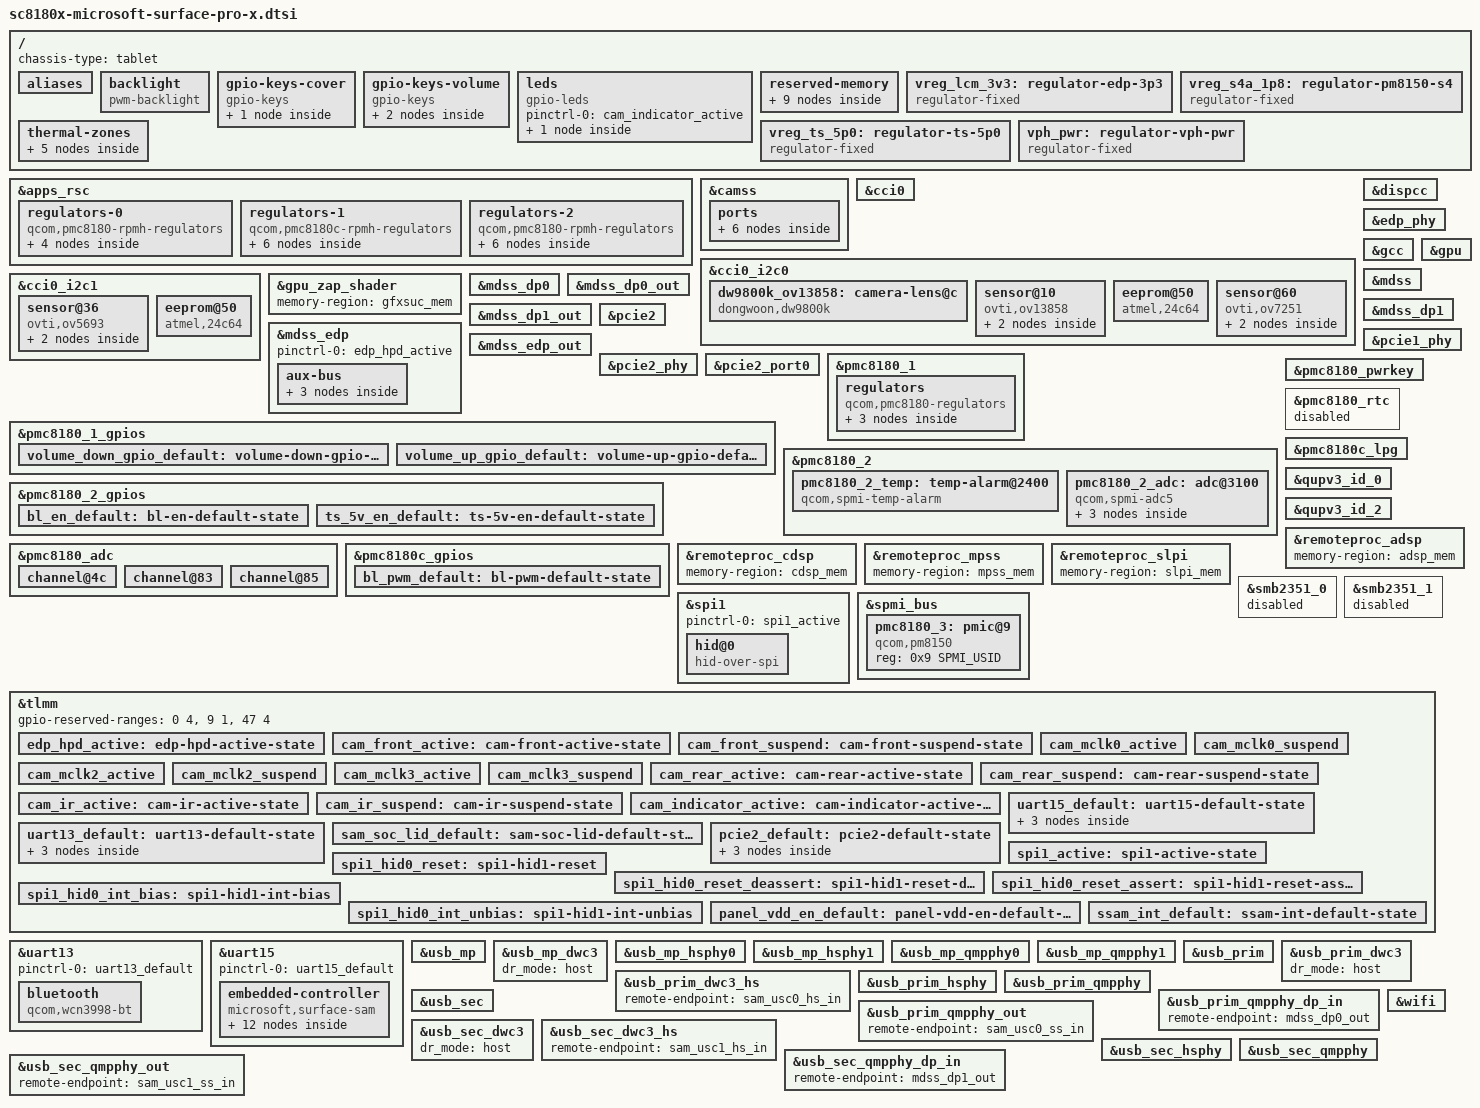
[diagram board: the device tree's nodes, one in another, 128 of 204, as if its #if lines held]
// SPDX-License-Identifier: (GPL-2.0+ OR BSD-3-Clause)
/*
 * Copyright (c) 2022-2026, Maximilian Luz <luzmaximilian@gmail.com>
 * Copyright (c) 2026, Val Packett <val@packett.cool>
 */

/dts-v1/;

#include <dt-bindings/firmware/qcom,scm.h>
#include <dt-bindings/gpio/gpio.h>
#include <dt-bindings/iio/qcom,spmi-vadc.h>
#include <dt-bindings/input/gpio-keys.h>
#include <dt-bindings/input/input.h>
#include <dt-bindings/interrupt-controller/irq.h>
#include <dt-bindings/leds/common.h>
#include <dt-bindings/media/video-interface-devices.h>
#include <dt-bindings/media/video-interfaces.h>
#include <dt-bindings/regulator/qcom,rpmh-regulator.h>
#include <dt-bindings/spmi/spmi.h>
#include "sc8180x.dtsi"
#include "sc8180x-pmics.dtsi"

/delete-node/ &gpu_mem;

/ {
	chassis-type = "tablet";

	aliases {
		serial0 = &uart13;
		serial1 = &uart15;
	};

	backlight: backlight {
		compatible = "pwm-backlight";

		pwms = <&pmc8180c_lpg 4 5000000>;
		enable-gpios = <&pmc8180_2_gpios 1 GPIO_ACTIVE_HIGH>;

		pinctrl-0 = <&bl_pwm_default &bl_en_default>;
		pinctrl-names = "default";
	};

	gpio-keys-cover {
		compatible = "gpio-keys";
		label = "Tablet Cover Switch";

		pinctrl-0 = <&sam_soc_lid_default>;
		pinctrl-names = "default";

		switch-cover {
			label = "Tablet Cover";
			gpios = <&tlmm 121 GPIO_ACTIVE_LOW>;
			linux,input-type = <EV_SW>;
			linux,code = <SW_LID>;
			wakeup-source;
			wakeup-event-action = <EV_ACT_DEASSERTED>;
		};
	};

	gpio-keys-volume {
		compatible = "gpio-keys";
		label = "Volume Buttons";
		autorepeat;

		pinctrl-0 = <&volume_down_gpio_default>,
			   <&volume_up_gpio_default>;
		pinctrl-names = "default";

		key-volume-down {
			label = "Volume Down";
			gpios = <&pmc8180_1_gpios 1 GPIO_ACTIVE_LOW>;
			wakeup-source;
			linux,code = <KEY_VOLUMEDOWN>;
		};

		key-volume-up {
			label = "Volume Up";
			gpios = <&pmc8180_1_gpios 6 GPIO_ACTIVE_LOW>;
			wakeup-source;
			linux,code = <KEY_VOLUMEUP>;
		};
	};

	leds {
		compatible = "gpio-leds";

		pinctrl-0 = <&cam_indicator_active>;
		pinctrl-names = "default";

		privacy_led: led-camera-indicator {
			label = "white:camera-indicator";
			function = LED_FUNCTION_INDICATOR;
			color = <LED_COLOR_ID_WHITE>;
			gpios = <&tlmm 25 GPIO_ACTIVE_HIGH>;
			linux,default-trigger = "none";
			default-state = "off";
			panic-indicator;
		};
	};

	reserved-memory {
		rmtfs_mem: memory@85500000 {
			compatible = "qcom,rmtfs-mem";
			reg = <0x0 0x85500000 0x0 0x200000>;
			no-map;

			qcom,client-id = <1>;
			qcom,vmid = <QCOM_SCM_VMID_MSS_MSA>;
		};

		wlan_mem: memory@8bc00000 {
			reg = <0x0 0x8bc00000 0x0 0x180000>;
			no-map;
		};

		mpss_mem: memory@8d800000 { /* non-relocatable */
			reg = <0x0 0x8d800000 0x0 0x9600000>;
			no-map;
		};

		adsp_mem: memory@96e00000 {
			reg = <0x0 0x96e00000 0x0 0x1c00000>;
			no-map;
		};

		cdsp_mem: memory@98a00000 {
			reg = <0x0 0x98a00000 0x0 0x800000>;
			no-map;
		};

		slpi_mem: memory@99200000 {
			reg = <0x0 0x99200000 0x0 0x1400000>;
			no-map;
		};

		venus_mem: memory@9a600000 {
			reg = <0x0 0x9a600000 0x0 0x500000>;
			no-map;
		};

		gfxsuc_mem: memory@9ab00000 {
			reg = <0x0 0x9ab00000 0x0 0x5000>;
			no-map;
		};

		linux,cma {
			compatible = "shared-dma-pool";
			size = <0x0 0x8000000>;
			reusable;
			linux,cma-default;
		};
	};

	vreg_lcm_3v3: regulator-edp-3p3 {
		compatible = "regulator-fixed";

		regulator-name = "VREG_LCM_3V3";
		regulator-min-microvolt = <3300000>;
		regulator-max-microvolt = <3300000>;

		gpio = <&tlmm 130 GPIO_ACTIVE_HIGH>;
		enable-active-high;

		pinctrl-0 = <&panel_vdd_en_default>;
		pinctrl-names = "default";

		regulator-boot-on;
	};

	vreg_s4a_1p8: regulator-pm8150-s4 {
		compatible = "regulator-fixed";
		regulator-name = "vreg_s4a_1p8";

		regulator-min-microvolt = <1800000>;
		regulator-max-microvolt = <1800000>;

		regulator-always-on;
		regulator-boot-on;

		vin-supply = <&vph_pwr>;
	};

	vreg_ts_5p0: regulator-ts-5p0 {
		compatible = "regulator-fixed";
		regulator-name = "vreg_ts_5p0";

		regulator-min-microvolt = <5000000>;
		regulator-max-microvolt = <5000000>;

		gpio = <&pmc8180_2_gpios 10 GPIO_ACTIVE_HIGH>;
		enable-active-high;

		pinctrl-names = "default";
		pinctrl-0 = <&ts_5v_en_default>;
	};

	vph_pwr: regulator-vph-pwr {
		compatible = "regulator-fixed";
		regulator-name = "vph_pwr";
		regulator-min-microvolt = <3700000>;
		regulator-max-microvolt = <3700000>;

		regulator-always-on;
		regulator-boot-on;
	};

	thermal-zones {
		pmc8180-2-thermal {
			polling-delay-passive = <100>;
			polling-delay = <0>;

			thermal-sensors = <&pmc8180_2_temp>;

			trips {
				trip0 {
					temperature = <95000>;
					hysteresis = <0>;
					type = "passive";
				};

				trip1 {
					temperature = <115000>;
					hysteresis = <0>;
					type = "hot";
				};

				trip2 {
					temperature = <145000>;
					hysteresis = <0>;
					type = "critical";
				};
			};
		};
	};
};

&apps_rsc {
	regulators-0 {
		compatible = "qcom,pmc8180-rpmh-regulators";
		qcom,pmic-id = "a";

		vdd-s1-supply = <&vph_pwr>;
		vdd-s2-supply = <&vph_pwr>;
		vdd-s3-supply = <&vph_pwr>;
		vdd-s4-supply = <&vph_pwr>;
		vdd-s5-supply = <&vph_pwr>;
		vdd-s6-supply = <&vph_pwr>;
		vdd-s7-supply = <&vph_pwr>;
		vdd-s8-supply = <&vph_pwr>;
		vdd-s9-supply = <&vph_pwr>;
		vdd-s10-supply = <&vph_pwr>;

		vdd-l1-l8-l11-supply = <&vreg_s6c_1p37>;
		vdd-l2-l10-supply = <&vreg_bob>;
		vdd-l3-l4-l5-l18-supply = <&vreg_s7c_0p96>;
		vdd-l6-l9-supply = <&vreg_s6c_1p37>;
		vdd-l7-l12-l14-l15-supply = <&vreg_s5a_2p04>;
		vdd-l13-l16-l17-supply = <&vreg_bob>;

		vreg_s5a_2p04: smps5 {
			regulator-min-microvolt = <2040000>;
			regulator-max-microvolt = <2040000>;
		};

		vreg_l7a_1p8: ldo7 {
			regulator-min-microvolt = <1800000>;
			regulator-max-microvolt = <1800000>;
			regulator-initial-mode = <RPMH_REGULATOR_MODE_HPM>;
		};

		vreg_l9a_1p3: ldo9 {
			regulator-min-microvolt = <1296000>;
			regulator-max-microvolt = <1304000>;
			regulator-initial-mode = <RPMH_REGULATOR_MODE_HPM>;
		};

		vreg_l12a_1p8: ldo12 {
			regulator-min-microvolt = <1800000>;
			regulator-max-microvolt = <1800000>;
			regulator-initial-mode = <RPMH_REGULATOR_MODE_HPM>;
		};
	};

	regulators-1 {
		compatible = "qcom,pmc8180c-rpmh-regulators";
		qcom,pmic-id = "c";

		vdd-s1-supply = <&vph_pwr>;
		vdd-s2-supply = <&vph_pwr>;
		vdd-s3-supply = <&vph_pwr>;
		vdd-s4-supply = <&vph_pwr>;
		vdd-s5-supply = <&vph_pwr>;
		vdd-s6-supply = <&vph_pwr>;
		vdd-s7-supply = <&vph_pwr>;
		vdd-s8-supply = <&vph_pwr>;

		vdd-l1-l8-supply = <&vreg_s4a_1p8>;
		vdd-l2-l3-supply = <&vreg_s6c_1p37>;
		vdd-l4-l5-l6-supply = <&vreg_bob>;
		vdd-l7-l11-supply = <&vreg_bob>;
		vdd-l9-l10-supply = <&vreg_bob>;

		vdd-bob-supply = <&vph_pwr>;
		vdd-flash-supply = <&vreg_bob>;
		vdd-rgb-supply = <&vreg_bob>;

		vreg_s6c_1p37: smps6 {
			regulator-min-microvolt = <1350000>;
			regulator-max-microvolt = <1372000>;
			regulator-initial-mode = <RPMH_REGULATOR_MODE_HPM>;
		};

		vreg_s7c_0p96: smps7 {
			regulator-min-microvolt = <960000>;
			regulator-max-microvolt = <960000>;
			regulator-initial-mode = <RPMH_REGULATOR_MODE_HPM>;
		};

		vreg_l3c_1p2: ldo3 {
			regulator-min-microvolt = <1200000>;
			regulator-max-microvolt = <1200000>;
			regulator-initial-mode = <RPMH_REGULATOR_MODE_HPM>;
		};

		vreg_l10c_3p3: ldo10 {
			regulator-min-microvolt = <3296000>;
			regulator-max-microvolt = <3312000>;
			regulator-initial-mode = <RPMH_REGULATOR_MODE_HPM>;
		};

		vreg_l11c_3p3: ldo11 {
			regulator-min-microvolt = <3296000>;
			regulator-max-microvolt = <3304000>;
			regulator-initial-mode = <RPMH_REGULATOR_MODE_HPM>;
		};

		vreg_bob: bob {
			regulator-min-microvolt = <3296000>;
			regulator-max-microvolt = <3350000>;
			regulator-initial-mode = <RPMH_REGULATOR_MODE_HPM>;
		};
	};

	regulators-2 {
		compatible = "qcom,pmc8180-rpmh-regulators";
		qcom,pmic-id = "e";

		vdd-s1-supply = <&vph_pwr>;
		vdd-s2-supply = <&vph_pwr>;
		vdd-s3-supply = <&vph_pwr>;
		vdd-s4-supply = <&vph_pwr>;
		vdd-s5-supply = <&vph_pwr>;
		vdd-s6-supply = <&vph_pwr>;
		vdd-s7-supply = <&vph_pwr>;
		vdd-s8-supply = <&vph_pwr>;
		vdd-s9-supply = <&vph_pwr>;
		vdd-s10-supply = <&vph_pwr>;

		vdd-l1-l8-l11-supply = <&vreg_s4e_0p99>;
		vdd-l2-l10-supply = <&vreg_bob>;
		vdd-l3-l4-l5-l18-supply = <&vreg_s4e_0p99>;
		vdd-l6-l9-supply = <&vreg_s4e_0p99>;
		vdd-l7-l12-l14-l15-supply = <&vreg_s5e_2p04>;
		vdd-l13-l16-l17-supply = <&vreg_bob>;

		vreg_s4e_0p99: smps4 {
			regulator-min-microvolt = <992000>;
			regulator-max-microvolt = <992000>;
			regulator-initial-mode = <RPMH_REGULATOR_MODE_HPM>;
		};

		vreg_s5e_2p04: smps5 {
			regulator-min-microvolt = <2040000>;
			regulator-max-microvolt = <2040000>;
			regulator-initial-mode = <RPMH_REGULATOR_MODE_HPM>;
		};

		vreg_l1e_0p75: ldo1 {
			regulator-min-microvolt = <752000>;
			regulator-max-microvolt = <752000>;
			regulator-initial-mode = <RPMH_REGULATOR_MODE_HPM>;
		};

		vreg_l5e_0p88: ldo5 {
			regulator-min-microvolt = <880000>;
			regulator-max-microvolt = <880000>;
			regulator-initial-mode = <RPMH_REGULATOR_MODE_HPM>;
		};

		vreg_l9e_0p88: ldo9 {
			regulator-min-microvolt = <880000>;
			regulator-max-microvolt = <880000>;
			regulator-initial-mode = <RPMH_REGULATOR_MODE_HPM>;
		};

		vreg_l16e_3p1: ldo16 {
			regulator-min-microvolt = <3072000>;
			regulator-max-microvolt = <3072000>;
			regulator-initial-mode = <RPMH_REGULATOR_MODE_HPM>;
		};
	};
};

&camss {
	vdda-phy-supply = <&vreg_l5e_0p88>;
	vdda-pll-supply = <&vreg_l3c_1p2>;
	status = "okay";

	ports {
		port@0 {
			csiphy0_lanes01_ep: endpoint {
				clock-lanes = <7>;
				data-lanes = <0 1>;
				remote-endpoint = <&ov5693_ep>;
			};
		};

		port@2 {
			csiphy2_ep: endpoint {
				data-lanes = <0 1 2 3>;
				remote-endpoint = <&ov13858_ep>;
			};
		};

		port@3 {
			csiphy3_lane0_ep: endpoint {
				clock-lanes = <7>;
				data-lanes = <0>;
				remote-endpoint = <&ov7251_ep>;
			};
		};
	};
};

&cci0 {
	status = "okay";
};

&cci0_i2c0 {
#ifdef NOTYET
	// XXX: doesn't like being accessed when camera itself is not streaming??
	dw9800k_ov13858: camera-lens@c {
		compatible = "dongwoon,dw9800k";
		reg = <0x0c>;

		vdd-supply = <&vreg_l17a_2p85>;

		dongwoon,sac-mode = <1>;
		dongwoon,vcm-prescale = <16>;
	};
#endif

	sensor@10 {
		compatible = "ovti,ov13858";
		reg = <0x10>;

		avdd-supply = <&vreg_l17a_2p85>;
		dovdd-supply = <&vreg_l14a_1p8>;
		dvdd-supply = <&vreg_l1a_1p2>;

		pinctrl-names = "default", "sleep";
		pinctrl-0 = <&cam_mclk0_active &cam_rear_active>;
		pinctrl-1 = <&cam_mclk0_suspend &cam_rear_suspend>;

		clocks = <&camcc CAM_CC_MCLK0_CLK>;
		assigned-clocks = <&camcc CAM_CC_MCLK0_CLK>;
		assigned-clock-rates = <19200000>;

		/* CAM_REAR_PWRDN_N, functions as inverted reset */
		reset-gpios = <&tlmm 22 GPIO_ACTIVE_LOW>;

		orientation = <MEDIA_ORIENTATION_BACK>;
		rotation = <180>;

		// lens-focus = <&dw9800k_ov13858>;

		port {
			ov13858_ep: endpoint {
				bus-type = <MEDIA_BUS_TYPE_CSI2_DPHY>;
				data-lanes = <1 2 3 4>;
				link-frequencies = /bits/ 64 <540000000 270000000>;
				remote-endpoint = <&csiphy2_ep>;
			};
		};
	};

	eeprom@50 {
		compatible = "atmel,24c64";
		reg = <0x50>;
		vcc-supply = <&vreg_l14a_1p8>;
		read-only;
	};

	sensor@60 {
		compatible = "ovti,ov7251";
		reg = <0x60>;

		vdda-supply = <&vreg_l14a_1p8>;
		vddd-supply = <&vreg_l14a_1p8>;
		vdddo-supply = <&vreg_l14a_1p8>;

		pinctrl-names = "default", "sleep";
		pinctrl-0 = <&cam_mclk3_active &cam_ir_active>;
		pinctrl-1 = <&cam_mclk3_suspend &cam_ir_suspend>;

		clocks = <&camcc CAM_CC_MCLK3_CLK>;
		clock-names = "xclk";
		assigned-clocks = <&camcc CAM_CC_MCLK3_CLK>;
		assigned-clock-rates = <19200000>;

		/* CAM_IR_PWRDN_N; driver's confused and treats reset as pwrdn */
		enable-gpios = <&tlmm 23 GPIO_ACTIVE_HIGH>;

		orientation = <MEDIA_ORIENTATION_FRONT>;

		port {
			ov7251_ep: endpoint {
				bus-type = <MEDIA_BUS_TYPE_CSI2_DPHY>;
				data-lanes = <1>;
				link-frequencies = /bits/ 64 <240000000 319200000>;
				remote-endpoint = <&csiphy3_lane0_ep>;
			};
		};
	};
};

&cci0_i2c1 {
	sensor@36 {
		compatible = "ovti,ov5693";
		reg = <0x36>;

		// LDO makes avdd2.8V, enabled also by l14a itself(!)
		avdd-supply = <&vreg_l14a_1p8>;
		dvdd-supply = <&vreg_l14a_1p8>;
		dovdd-supply = <&vreg_l14a_1p8>;

		pinctrl-names = "default", "sleep";
		pinctrl-0 = <&cam_mclk2_active &cam_front_active>;
		pinctrl-1 = <&cam_mclk2_suspend &cam_front_suspend>;

		/* CAM_FRONT_PWRDN_N; driver's confused and treats reset as pwrdn */
		reset-gpios = <&tlmm 12 GPIO_ACTIVE_LOW>;

		clocks = <&camcc CAM_CC_MCLK2_CLK>;
		clock-names = "xvclk";
		assigned-clocks = <&camcc CAM_CC_MCLK2_CLK>;
		assigned-clock-rates = <19200000>;

		orientation = <MEDIA_ORIENTATION_FRONT>;
		rotation = <180>;

		leds = <&privacy_led>;
		led-names = "privacy";

		port {
			ov5693_ep: endpoint {
				bus-type = <MEDIA_BUS_TYPE_CSI2_DPHY>;
				data-lanes = <1 2>;
				link-frequencies = /bits/ 64 <419200000>;
				remote-endpoint = <&csiphy0_lanes01_ep>;
			};
		};
	};

	eeprom@50 {
		compatible = "atmel,24c64";
		reg = <0x50>;
		vcc-supply = <&vreg_l14a_1p8>;
		read-only;
	};
};

&dispcc {
	status = "okay";
};

&edp_phy {
	vdda-pll-supply = <&vreg_l5e_0p88>;
	vdda-phy-supply = <&vreg_l3c_1p2>;
};

&gcc {
	protected-clocks = <GCC_QSPI_CORE_CLK>,
			   <GCC_QSPI_CORE_CLK_SRC>,
			   <GCC_QSPI_CNOC_PERIPH_AHB_CLK>;
};

&gpu {
	status = "okay";
};

&gpu_zap_shader {
	memory-region = <&gfxsuc_mem>;
};

&mdss {
	status = "okay";
};

&mdss_dp0 {
	status = "okay";
};

&mdss_dp0_out {
	data-lanes = <0 1>;
	remote-endpoint = <&usb_prim_qmpphy_dp_in>;
};

&mdss_dp1 {
	status = "okay";
};

&mdss_dp1_out {
	data-lanes = <0 1>;
	remote-endpoint = <&usb_sec_qmpphy_dp_in>;
};

&mdss_edp {
	pinctrl-0 = <&edp_hpd_active>;
	pinctrl-names = "default";

	status = "okay";

	aux-bus {
		panel {
			compatible = "edp-panel";
			power-supply = <&vreg_lcm_3v3>;

			backlight = <&backlight>;

			port {
				edp_panel_in: endpoint {
					remote-endpoint = <&mdss_edp_out>;
				};
			};
		};
	};
};

&mdss_edp_out {
	data-lanes = <0 1 2 3>;
	remote-endpoint = <&edp_panel_in>;
};

&pcie1_phy {
	vdda-phy-supply = <&vreg_l5e_0p88>;
	vdda-pll-supply = <&vreg_l3c_1p2>;

	status = "okay";
};

&pcie2 {
	// XXX: pcie1 and pcie2 are multi'd together, for now use just one
	num-lanes = <2>;

	pinctrl-0 = <&pcie2_default>;
	pinctrl-names = "default";

	// XXX: Remove "global" interrupt (breaks the multi workaround)
	interrupts = <GIC_SPI 672 IRQ_TYPE_LEVEL_HIGH>,
		     <GIC_SPI 671 IRQ_TYPE_LEVEL_HIGH>,
		     <GIC_SPI 670 IRQ_TYPE_LEVEL_HIGH>,
		     <GIC_SPI 669 IRQ_TYPE_LEVEL_HIGH>,
		     <GIC_SPI 668 IRQ_TYPE_LEVEL_HIGH>,
		     <GIC_SPI 667 IRQ_TYPE_LEVEL_HIGH>,
		     <GIC_SPI 666 IRQ_TYPE_LEVEL_HIGH>,
		     <GIC_SPI 665 IRQ_TYPE_LEVEL_HIGH>;
	interrupt-names = "msi0",
			  "msi1",
			  "msi2",
			  "msi3",
			  "msi4",
			  "msi5",
			  "msi6",
			  "msi7";

	status = "okay";
};

&pcie2_phy {
	vdda-phy-supply = <&vreg_l5e_0p88>;
	vdda-pll-supply = <&vreg_l3c_1p2>;

	status = "okay";
};

&pcie2_port0 {
	reset-gpios = <&tlmm 102 GPIO_ACTIVE_LOW>;
	wake-gpios = <&tlmm 104 GPIO_ACTIVE_LOW>;
};

&pmc8180_1 {
	regulators {
		compatible = "qcom,pmc8180-regulators";

		vdd_l1_l8_l11-supply = <&vreg_s6c_1p37>;
		vdd_l7_l12_l14_l15-supply = <&vreg_s5a_2p04>;
		vdd_l13_l16_l17-supply = <&vreg_bob>;

		vreg_l1a_1p2: l1 {
			regulator-name = "vreg_l1a_1p2";
			regulator-min-microvolt = <1200000>;
			regulator-max-microvolt = <1200000>;
			regulator-enable-ramp-delay = <10000>;
		};

		vreg_l14a_1p8: l14 {
			regulator-name = "vreg_l14a_1p8";
			regulator-min-microvolt = <1800000>;
			regulator-max-microvolt = <1800000>;
			regulator-enable-ramp-delay = <10000>;
		};

		vreg_l17a_2p85: l17 {
			regulator-name = "vreg_l17a_2p85";
			regulator-min-microvolt = <2848000>;
			regulator-max-microvolt = <2848000>;
			regulator-enable-ramp-delay = <10000>;
		};
	};
};

&pmc8180_1_gpios {
	volume_down_gpio_default: volume-down-gpio-default-state {
		pins = "gpio1";
		function = "normal";

		input-enable;
		bias-pull-up;

		qcom,drive-strength = <0>;
	};

	volume_up_gpio_default: volume-up-gpio-default-state {
		pins = "gpio6";
		function = "normal";

		input-enable;
		bias-pull-up;

		qcom,drive-strength = <0>;
	};
};

&pmc8180_2 {
	pmc8180_2_temp: temp-alarm@2400 {
		compatible = "qcom,spmi-temp-alarm";
		reg = <0x2400>;
		interrupts = <0x8 0x24 0x0 IRQ_TYPE_EDGE_BOTH>;
		io-channels = <&pmc8180_2_adc ADC5_DIE_TEMP>;
		io-channel-names = "thermal";
		#thermal-sensor-cells = <0>;
	};

	pmc8180_2_adc: adc@3100 {
		compatible = "qcom,spmi-adc5";
		reg = <0x3100>;
		#address-cells = <1>;
		#size-cells = <0>;
		#io-channel-cells = <1>;
		interrupts = <0x8 0x31 0x0 IRQ_TYPE_EDGE_RISING>;

		channel@0 {
			reg = <ADC5_REF_GND>;
			qcom,pre-scaling = <1 1>;
			label = "ref_gnd";
		};

		channel@1 {
			reg = <ADC5_1P25VREF>;
			qcom,pre-scaling = <1 1>;
			label = "vref_1p25";
		};

		channel@6 {
			reg = <ADC5_DIE_TEMP>;
			qcom,pre-scaling = <1 1>;
			label = "die_temp";
		};
	};
};

&pmc8180_2_gpios {
	bl_en_default: bl-en-default-state {
		pins = "gpio1";
		function = "normal";
	};

	ts_5v_en_default: ts-5v-en-default-state {
		pins = "gpio10";
		function = "normal";
	};
};

&pmc8180_adc {
	channel@4c {
		reg = <ADC5_XO_THERM_100K_PU>;
		qcom,ratiometric;
		qcom,pre-scaling = <1 1>;
		qcom,hw-settle-time = <200>;
		label = "xo_therm";
	};

	channel@83 {
		reg = <ADC5_VPH_PWR>;
		qcom,pre-scaling = <1 3>;
		label = "vph_pwr";
	};

	channel@85 {
		reg = <ADC5_VCOIN>;
		qcom,pre-scaling = <1 3>;
		label = "vcoin";
	};
};

&pmc8180_pwrkey {
	status = "okay";
};

&pmc8180_rtc {
	status = "disabled";
};

&pmc8180c_gpios {
	bl_pwm_default: bl-pwm-default-state {
		pins = "gpio10";
		function = "func1";
	};
};

&pmc8180c_lpg {
	status = "okay";
};

&qupv3_id_0 {
	status = "okay";
};

&qupv3_id_2 {
	status = "okay";
};

&remoteproc_adsp {
	memory-region = <&adsp_mem>;
};

&remoteproc_cdsp {
	memory-region = <&cdsp_mem>;
};

&remoteproc_mpss {
	memory-region = <&mpss_mem>;
};

&remoteproc_slpi {
	memory-region = <&slpi_mem>;
};

&smb2351_0 {
	status = "disabled";
};

&smb2351_1 {
	status = "disabled";
};

&spi1 {
	pinctrl-names = "default";
	pinctrl-0 = <&spi1_active>;

	status = "okay";

	hid@0 {
		compatible = "hid-over-spi";

		reg = <0>;
		spi-max-frequency = <25000000>;

		interrupts-extended = <&tlmm 122 IRQ_TYPE_EDGE_FALLING>;

		vdd-supply = <&vreg_ts_5p0>;

		pinctrl-0 = <&spi1_hid0_reset_deassert &spi1_hid0_int_bias>;
		pinctrl-1 = <&spi1_hid0_reset_assert &spi1_hid0_int_unbias>;
		pinctrl-2 = <&spi1_hid0_reset_assert &spi1_hid0_int_bias>;
		pinctrl-names = "active", "sleep", "reset";
		hid-descr-addr = <1>;
	};
};

&spmi_bus {
	pmc8180_3: pmic@9 {
		compatible = "qcom,pm8150", "qcom,spmi-pmic";
		reg = <0x9 SPMI_USID>;
		#address-cells = <1>;
		#size-cells = <0>;
	};
};

&tlmm {
	gpio-reserved-ranges = <0 4>, /* TPM_STRAP, eSE SPI */
			       <9 1>, /* TPM IRQ */
			       <47 4> /* SPI14 (TPM) */;

	edp_hpd_active: edp-hpd-active-state {
		pins = "gpio10";
		function = "edp_hot";
	};

	cam_front_active: cam-front-active-state {
		pins = "gpio12";
		function = "gpio";

		bias-disable;
		drive-strength = <2>;
	};

	cam_front_suspend: cam-front-suspend-state {
		pins = "gpio12";
		function = "gpio";

		bias-pull-down;
		drive-strength = <2>;
		output-low;
	};

	cam_mclk0_active: cam_mclk0_active {
		pins = "gpio13";
		function = "cam_mclk";

		bias-disable;
		drive-strength = <2>;
	};

	cam_mclk0_suspend: cam_mclk0_suspend {
		pins = "gpio13";
		function = "cam_mclk";

		bias-pull-down;
		drive-strength = <2>;
	};

	cam_mclk2_active: cam_mclk2_active {
		pins = "gpio15";
		function = "cam_mclk";

		bias-disable;
		drive-strength = <2>;
	};

	cam_mclk2_suspend: cam_mclk2_suspend {
		pins = "gpio15";
		function = "cam_mclk";

		bias-pull-down;
		drive-strength = <2>;
	};

	cam_mclk3_active: cam_mclk3_active {
		pins = "gpio16";
		function = "cam_mclk";

		bias-disable;
		drive-strength = <2>;
	};

	cam_mclk3_suspend: cam_mclk3_suspend {
		pins = "gpio16";
		function = "cam_mclk";

		bias-pull-down;
		drive-strength = <2>;
	};

	cam_rear_active: cam-rear-active-state {
		pins = "gpio22";
		function = "gpio";

		bias-disable;
		drive-strength = <2>;
	};

	cam_rear_suspend: cam-rear-suspend-state {
		pins = "gpio22";
		function = "gpio";

		bias-pull-down;
		drive-strength = <2>;
		output-low;
	};

	cam_ir_active: cam-ir-active-state {
		pins = "gpio23";
		function = "gpio";

		bias-disable;
		drive-strength = <2>;
	};

	cam_ir_suspend: cam-ir-suspend-state {
		pins = "gpio23";
		function = "gpio";

		bias-pull-down;
		drive-strength = <2>;
		output-low;
	};

	cam_indicator_active: cam-indicator-active-state {
		pins = "gpio25";
		function = "gpio";

		drive-strength = <2>;
		bias-disable;
	};

	uart15_default: uart15-default-state {
		cts-pins {
			pins = "gpio27";
			function = "qup15";

			bias-pull-down;
		};

		rts-tx-pins {
			pins = "gpio28", "gpio29";
			function = "qup15";
			drive-strength = <2>;

			bias-disable;
		};

		rx-pins {
			pins = "gpio30";
			function = "qup15";

			bias-pull-up;
		};
	};

	uart13_default: uart13-default-state {
		cts-pins {
			pins = "gpio43";
			function = "qup13";

			bias-pull-down;
		};

		rts-tx-pins {
			pins = "gpio44", "gpio45";
			function = "qup13";
			drive-strength = <2>;

			bias-disable;
		};

		rx-pins {
			pins = "gpio46";
			function = "qup13";

			bias-pull-up;
		};
	};

	sam_soc_lid_default: sam-soc-lid-default-state {
		pins = "gpio121";
		function = "gpio";

		bias-disable;
	};

	pcie2_default: pcie2-default-state {
		clkreq-n-pins {
			pins = "gpio176";
			function = "pci_e2";
			drive-strength = <2>;

			bias-pull-up;
		};

		perst-n-pins {
			pins = "gpio102";
			function = "gpio";
			drive-strength = <2>;

			bias-disable;
		};

		wake-n-pins {
			pins = "gpio104";
			function = "gpio";
			drive-strength = <2>;

			bias-pull-up;
		};
	};

	spi1_active: spi1-active-state {
		pins = "gpio114", "gpio115", "gpio116", "gpio117";
		function = "qup1";

		drive-strength = <6>;
		bias-disable;
	};

	spi1_hid0_reset: spi1-hid1-reset {
		pins = "gpio54";
		function = "gpio";
		drive-strength = <2>;

		bias-disable;
	};

	spi1_hid0_reset_deassert: spi1-hid1-reset-deassert {
		pins = "gpio54";
		function = "gpio";
		drive-strength = <2>;

		bias-disable;
		output-high;
	};

	spi1_hid0_reset_assert: spi1-hid1-reset-assert {
		pins = "gpio54";
		function = "gpio";
		drive-strength = <2>;

		bias-disable;
		output-low;
	};

	spi1_hid0_int_bias: spi1-hid1-int-bias {
		pins = "gpio122";
		function = "gpio";

		input-enable;
		bias-pull-up;
	};

	spi1_hid0_int_unbias: spi1-hid1-int-unbias {
		pins = "gpio122";
		function = "gpio";

		input-enable;
		bias-disable;
	};

	panel_vdd_en_default: panel-vdd-en-default-state {
		pins = "gpio130";
		function = "gpio";

		drive-strength = <2>;
		bias-disable;
	};

	ssam_int_default: ssam-int-default-state {
		pins = "gpio180";
		function = "gpio";

		bias-disable;
	};
};

&uart13 {
	pinctrl-0 = <&uart13_default>;
	pinctrl-names = "default";

	status = "okay";

	bluetooth {
		compatible = "qcom,wcn3998-bt";

		vddio-supply = <&vreg_s4a_1p8>;
		vddxo-supply = <&vreg_l7a_1p8>;
		vddrf-supply = <&vreg_l9a_1p3>;
		vddch0-supply = <&vreg_l11c_3p3>;

		max-speed = <3200000>;
	};
};

&uart15 {
	pinctrl-0 = <&uart15_default>;
	pinctrl-names = "default";

	status = "okay";

	embedded-controller {
		compatible = "microsoft,surface-sam";

		interrupts-extended = <&tlmm 180 IRQ_TYPE_EDGE_RISING>;

		current-speed = <4000000>;

		pinctrl-0 = <&ssam_int_default>;
		pinctrl-names = "default";

		#address-cells = <1>;
		#size-cells = <0>;

		/* Lower port */
		connector@0 {
			compatible = "usb-c-connector";
			reg = <0>;
			power-role = "sink";
			data-role = "host";

			ports {
				#address-cells = <1>;
				#size-cells = <0>;

				port@0 {
					reg = <0>;

					sam_usc0_hs_in: endpoint {
						remote-endpoint = <&usb_prim_dwc3_hs>;
					};
				};

				port@1 {
					reg = <1>;

					sam_usc0_ss_in: endpoint {
						remote-endpoint = <&usb_prim_qmpphy_out>;
					};
				};
			};
		};

		/* Upper port */
		connector@1 {
			compatible = "usb-c-connector";
			reg = <1>;
			power-role = "sink";
			data-role = "host";

			ports {
				#address-cells = <1>;
				#size-cells = <0>;

				port@0 {
					reg = <0>;

					sam_usc1_hs_in: endpoint {
						remote-endpoint = <&usb_sec_dwc3_hs>;
					};
				};

				port@1 {
					reg = <1>;

					sam_usc1_ss_in: endpoint {
						remote-endpoint = <&usb_sec_qmpphy_out>;
					};
				};
			};
		};
	};
};

&usb_mp {
	status = "okay";
};

&usb_mp_dwc3 {
	dr_mode = "host";
};

&usb_mp_hsphy0 {
	vdda-pll-supply = <&vreg_l9e_0p88>;
	vdda18-supply = <&vreg_l12a_1p8>;
	vdda33-supply = <&vreg_l16e_3p1>;

	status = "okay";
};

&usb_mp_hsphy1 {
	vdda-pll-supply = <&vreg_l9e_0p88>;
	vdda18-supply = <&vreg_l12a_1p8>;
	vdda33-supply = <&vreg_l16e_3p1>;

	status = "okay";
};

&usb_mp_qmpphy0 {
	vdda-phy-supply = <&vreg_l3c_1p2>;
	vdda-pll-supply = <&vreg_l9e_0p88>;

	status = "okay";
};

&usb_mp_qmpphy1 {
	vdda-phy-supply = <&vreg_l3c_1p2>;
	vdda-pll-supply = <&vreg_l9e_0p88>;

	status = "okay";
};

&usb_prim {
	status = "okay";
};

&usb_prim_dwc3 {
	dr_mode = "host";
};

&usb_prim_dwc3_hs {
	remote-endpoint = <&sam_usc0_hs_in>;
};

&usb_prim_hsphy {
	vdda-pll-supply = <&vreg_l9e_0p88>;
	vdda18-supply = <&vreg_l12a_1p8>;
	vdda33-supply = <&vreg_l16e_3p1>;

	status = "okay";
};

&usb_prim_qmpphy {
	vdda-phy-supply = <&vreg_l9e_0p88>;
	vdda-pll-supply = <&vreg_l3c_1p2>;

	orientation-switch;

	status = "okay";
};

&usb_prim_qmpphy_dp_in {
	remote-endpoint = <&mdss_dp0_out>;
};

&usb_prim_qmpphy_out {
	remote-endpoint = <&sam_usc0_ss_in>;
};

&usb_sec {
	status = "okay";
};

&usb_sec_dwc3 {
	dr_mode = "host";
};

&usb_sec_dwc3_hs {
	remote-endpoint = <&sam_usc1_hs_in>;
};

&usb_sec_hsphy {
	vdda-pll-supply = <&vreg_l9e_0p88>;
	vdda18-supply = <&vreg_l12a_1p8>;
	vdda33-supply = <&vreg_l16e_3p1>;

	status = "okay";
};

&usb_sec_qmpphy {
	vdda-phy-supply = <&vreg_l9e_0p88>;
	vdda-pll-supply = <&vreg_l3c_1p2>;

	orientation-switch;

	status = "okay";
};

&usb_sec_qmpphy_dp_in {
	remote-endpoint = <&mdss_dp1_out>;
};

&usb_sec_qmpphy_out {
	remote-endpoint = <&sam_usc1_ss_in>;
};

&wifi {
	memory-region = <&wlan_mem>;

	vdd-0.8-cx-mx-supply = <&vreg_l1e_0p75>;
	vdd-1.8-xo-supply = <&vreg_l7a_1p8>;
	vdd-1.3-rfa-supply = <&vreg_l9a_1p3>;
	vdd-3.3-ch0-supply = <&vreg_l11c_3p3>;
	vdd-3.3-ch1-supply = <&vreg_l10c_3p3>;

	status = "okay";
};
